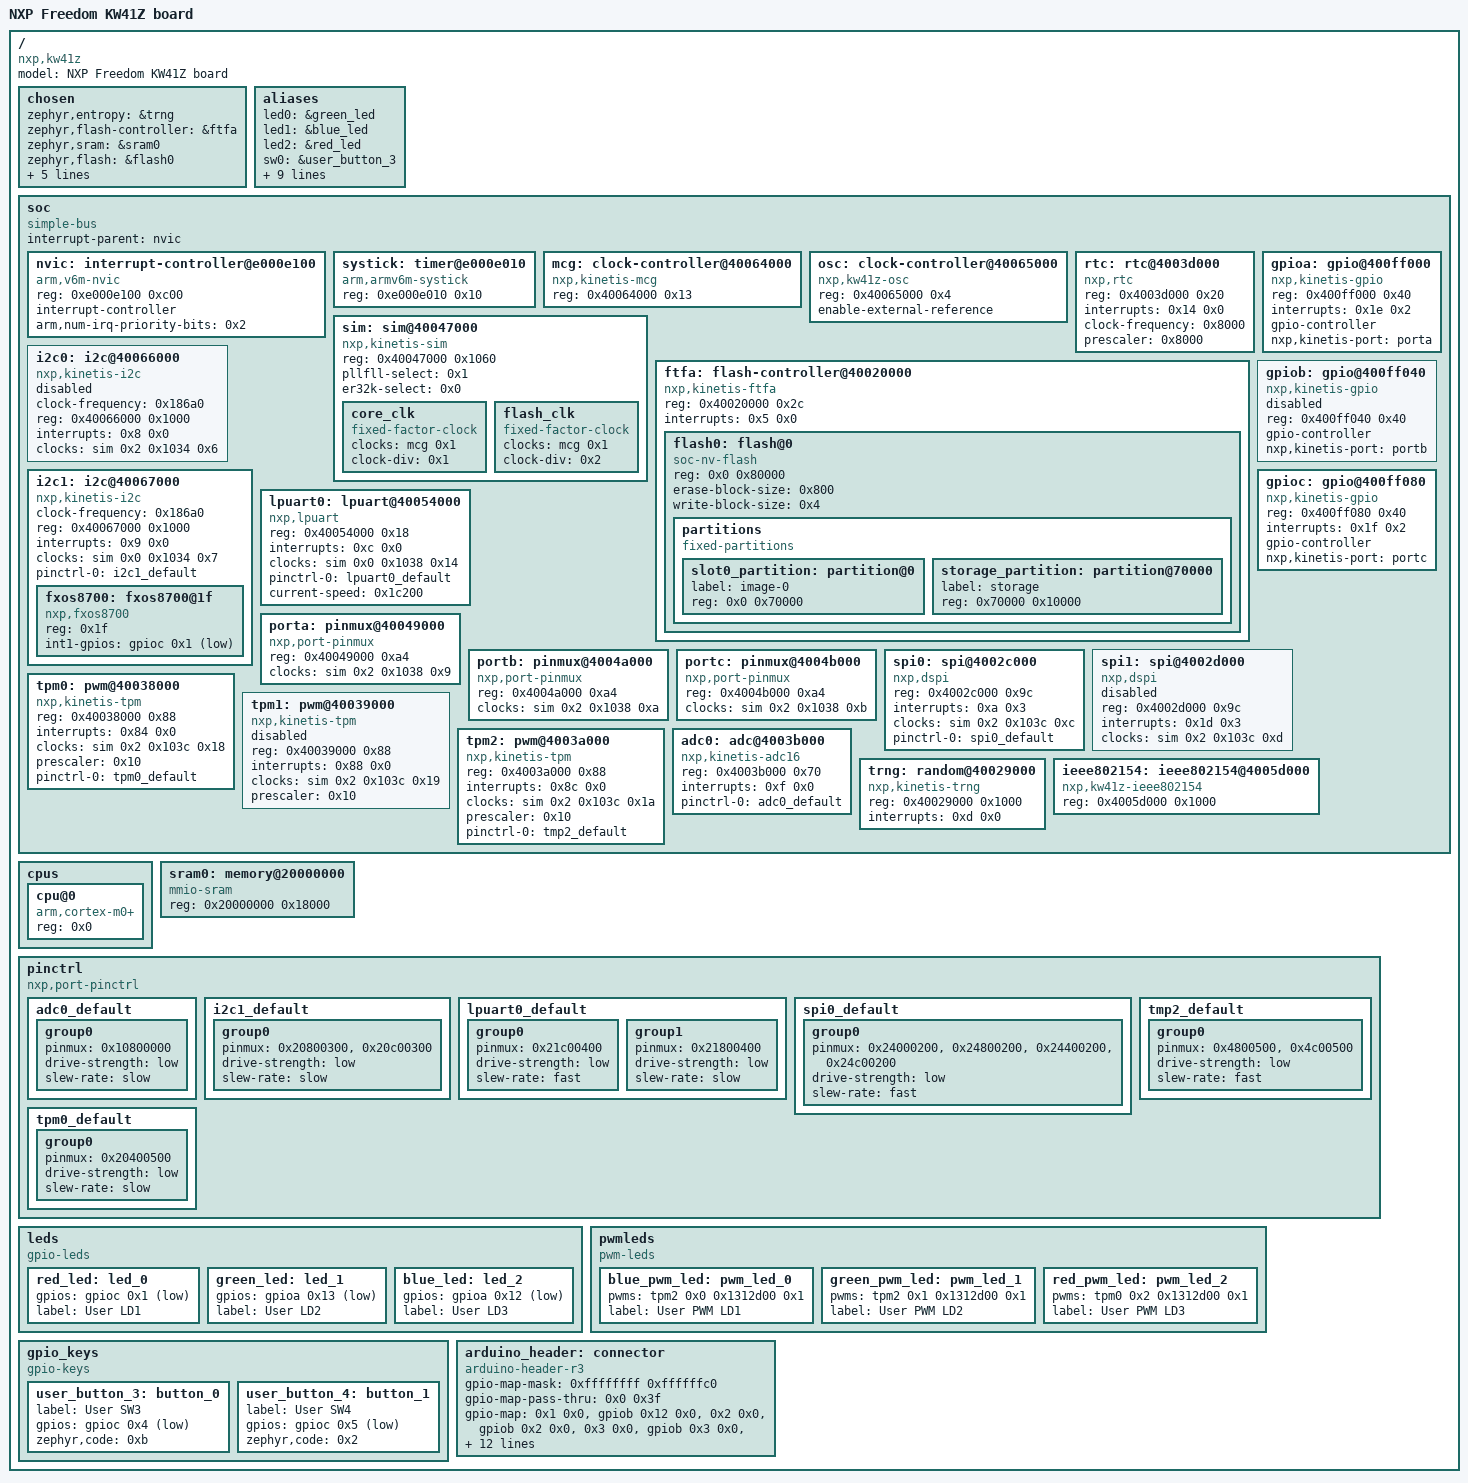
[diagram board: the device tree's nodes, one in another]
/dts-v1/;

/* node '/' defined in zephyr/dts/common/skeleton.dtsi:9 */
/ {
	#address-cells = < 0x1 >;          /* in zephyr/dts/common/skeleton.dtsi:10 */
	#size-cells = < 0x1 >;             /* in zephyr/dts/common/skeleton.dtsi:11 */
	model = "NXP Freedom KW41Z board"; /* in zephyr/boards/nxp/frdm_kw41z/frdm_kw41z.dts:11 */
	compatible = "nxp,kw41z",
	             "nxp,mkw41z4";        /* in zephyr/boards/nxp/frdm_kw41z/frdm_kw41z.dts:12 */

	/* node '/chosen' defined in zephyr/dts/common/skeleton.dtsi:13 */
	chosen {
		zephyr,entropy = &trng;                   /* in zephyr/dts/arm/nxp/nxp_kw41z.dtsi:19 */
		zephyr,flash-controller = &ftfa;          /* in zephyr/dts/arm/nxp/nxp_kw41z.dtsi:20 */
		zephyr,sram = &sram0;                     /* in zephyr/boards/nxp/frdm_kw41z/frdm_kw41z.dts:31 */
		zephyr,flash = &flash0;                   /* in zephyr/boards/nxp/frdm_kw41z/frdm_kw41z.dts:32 */
		zephyr,console = &lpuart0;                /* in zephyr/boards/nxp/frdm_kw41z/frdm_kw41z.dts:33 */
		zephyr,shell-uart = &lpuart0;             /* in zephyr/boards/nxp/frdm_kw41z/frdm_kw41z.dts:34 */
		zephyr,ieee802154 = &ieee802154;          /* in zephyr/boards/nxp/frdm_kw41z/frdm_kw41z.dts:35 */
		zephyr,code-partition = &slot0_partition; /* in zephyr/boards/nxp/frdm_kw41z/frdm_kw41z.dts:36 */
		zephyr,uart-mcumgr = &lpuart0;            /* in zephyr/boards/nxp/frdm_kw41z/frdm_kw41z.dts:37 */
	};

	/* node '/aliases' defined in zephyr/dts/common/skeleton.dtsi:15 */
	aliases {
		led0 = &green_led;              /* in zephyr/boards/nxp/frdm_kw41z/frdm_kw41z.dts:15 */
		led1 = &blue_led;               /* in zephyr/boards/nxp/frdm_kw41z/frdm_kw41z.dts:16 */
		led2 = &red_led;                /* in zephyr/boards/nxp/frdm_kw41z/frdm_kw41z.dts:17 */
		sw0 = &user_button_3;           /* in zephyr/boards/nxp/frdm_kw41z/frdm_kw41z.dts:18 */
		sw1 = &user_button_4;           /* in zephyr/boards/nxp/frdm_kw41z/frdm_kw41z.dts:19 */
		pwm-led0 = &blue_pwm_led;       /* in zephyr/boards/nxp/frdm_kw41z/frdm_kw41z.dts:20 */
		pwm-led1 = &green_pwm_led;      /* in zephyr/boards/nxp/frdm_kw41z/frdm_kw41z.dts:21 */
		pwm-led2 = &red_pwm_led;        /* in zephyr/boards/nxp/frdm_kw41z/frdm_kw41z.dts:22 */
		blue-pwm-led = &blue_pwm_led;   /* in zephyr/boards/nxp/frdm_kw41z/frdm_kw41z.dts:23 */
		green-pwm-led = &green_pwm_led; /* in zephyr/boards/nxp/frdm_kw41z/frdm_kw41z.dts:24 */
		red-pwm-led = &red_pwm_led;     /* in zephyr/boards/nxp/frdm_kw41z/frdm_kw41z.dts:25 */
		magn0 = &fxos8700;              /* in zephyr/boards/nxp/frdm_kw41z/frdm_kw41z.dts:26 */
		accel0 = &fxos8700;             /* in zephyr/boards/nxp/frdm_kw41z/frdm_kw41z.dts:27 */
	};

	/* node '/soc' defined in zephyr/dts/arm/armv6-m.dtsi:6 */
	soc {
		#address-cells = < 0x1 >;     /* in zephyr/dts/arm/armv6-m.dtsi:7 */
		#size-cells = < 0x1 >;        /* in zephyr/dts/arm/armv6-m.dtsi:8 */
		compatible = "simple-bus";    /* in zephyr/dts/arm/armv6-m.dtsi:9 */
		interrupt-parent = < &nvic >; /* in zephyr/dts/arm/armv6-m.dtsi:10 */
		ranges;                       /* in zephyr/dts/arm/armv6-m.dtsi:11 */

		/* node '/soc/interrupt-controller@e000e100' defined in zephyr/dts/arm/armv6-m.dtsi:13 */
		nvic: interrupt-controller@e000e100 {
			#address-cells = < 0x1 >;            /* in zephyr/dts/arm/armv6-m.dtsi:14 */
			compatible = "arm,v6m-nvic";         /* in zephyr/dts/arm/armv6-m.dtsi:15 */
			reg = < 0xe000e100 0xc00 >;          /* in zephyr/dts/arm/armv6-m.dtsi:16 */
			interrupt-controller;                /* in zephyr/dts/arm/armv6-m.dtsi:17 */
			#interrupt-cells = < 0x2 >;          /* in zephyr/dts/arm/armv6-m.dtsi:18 */
			arm,num-irq-priority-bits = < 0x2 >; /* in zephyr/dts/arm/nxp/nxp_kw41z.dtsi:259 */
			phandle = < 0x1 >;                   /* in zephyr/dts/arm/armv6-m.dtsi:10 */
		};

		/* node '/soc/timer@e000e010' defined in zephyr/dts/arm/armv6-m.dtsi:21 */
		systick: timer@e000e010 {
			compatible = "arm,armv6m-systick"; /* in zephyr/dts/arm/armv6-m.dtsi:22 */
			reg = < 0xe000e010 0x10 >;         /* in zephyr/dts/arm/armv6-m.dtsi:23 */
		};

		/* node '/soc/clock-controller@40064000' defined in zephyr/dts/arm/nxp/nxp_kw41z.dtsi:46 */
		mcg: clock-controller@40064000 {
			compatible = "nxp,kinetis-mcg"; /* in zephyr/dts/arm/nxp/nxp_kw41z.dtsi:47 */
			reg = < 0x40064000 0x13 >;      /* in zephyr/dts/arm/nxp/nxp_kw41z.dtsi:48 */
			#clock-cells = < 0x1 >;         /* in zephyr/dts/arm/nxp/nxp_kw41z.dtsi:49 */
			phandle = < 0x2 >;              /* in zephyr/dts/arm/nxp/nxp_kw41z.dtsi:73 */
		};

		/* node '/soc/clock-controller@40065000' defined in zephyr/dts/arm/nxp/nxp_kw41z.dtsi:52 */
		osc: clock-controller@40065000 {
			compatible = "nxp,kw41z-osc"; /* in zephyr/dts/arm/nxp/nxp_kw41z.dtsi:53 */
			reg = < 0x40065000 0x4 >;     /* in zephyr/dts/arm/nxp/nxp_kw41z.dtsi:54 */
			enable-external-reference;    /* in zephyr/dts/arm/nxp/nxp_kw41z.dtsi:55 */
		};

		/* node '/soc/rtc@4003d000' defined in zephyr/dts/arm/nxp/nxp_kw41z.dtsi:58 */
		rtc: rtc@4003d000 {
			compatible = "nxp,rtc";       /* in zephyr/dts/arm/nxp/nxp_kw41z.dtsi:59 */
			reg = < 0x4003d000 0x20 >;    /* in zephyr/dts/arm/nxp/nxp_kw41z.dtsi:60 */
			interrupts = < 0x14 0x0 >;    /* in zephyr/dts/arm/nxp/nxp_kw41z.dtsi:61 */
			clock-frequency = < 0x8000 >; /* in zephyr/dts/arm/nxp/nxp_kw41z.dtsi:62 */
			prescaler = < 0x8000 >;       /* in zephyr/dts/arm/nxp/nxp_kw41z.dtsi:63 */
		};

		/* node '/soc/sim@40047000' defined in zephyr/dts/arm/nxp/nxp_kw41z.dtsi:66 */
		sim: sim@40047000 {
			compatible = "nxp,kinetis-sim"; /* in zephyr/dts/arm/nxp/nxp_kw41z.dtsi:67 */
			reg = < 0x40047000 0x1060 >;    /* in zephyr/dts/arm/nxp/nxp_kw41z.dtsi:68 */
			#clock-cells = < 0x3 >;         /* in zephyr/dts/arm/nxp/nxp_kw41z.dtsi:69 */
			pllfll-select = < 0x1 >;        /* in zephyr/boards/nxp/frdm_kw41z/frdm_kw41z.dts:124 */
			er32k-select = < 0x0 >;         /* in zephyr/boards/nxp/frdm_kw41z/frdm_kw41z.dts:125 */
			phandle = < 0x3 >;              /* in zephyr/dts/arm/nxp/nxp_kw41z.dtsi:110 */

			/* node '/soc/sim@40047000/core_clk' defined in zephyr/dts/arm/nxp/nxp_kw41z.dtsi:71 */
			core_clk {
				compatible = "fixed-factor-clock"; /* in zephyr/dts/arm/nxp/nxp_kw41z.dtsi:72 */
				clocks = < &mcg 0x1 >;             /* in zephyr/dts/arm/nxp/nxp_kw41z.dtsi:73 */
				clock-div = < 0x1 >;               /* in zephyr/dts/arm/nxp/nxp_kw41z.dtsi:74 */
				#clock-cells = < 0x0 >;            /* in zephyr/dts/arm/nxp/nxp_kw41z.dtsi:75 */
			};

			/* node '/soc/sim@40047000/flash_clk' defined in zephyr/dts/arm/nxp/nxp_kw41z.dtsi:78 */
			flash_clk {
				compatible = "fixed-factor-clock"; /* in zephyr/dts/arm/nxp/nxp_kw41z.dtsi:79 */
				clocks = < &mcg 0x1 >;             /* in zephyr/dts/arm/nxp/nxp_kw41z.dtsi:80 */
				clock-div = < 0x2 >;               /* in zephyr/dts/arm/nxp/nxp_kw41z.dtsi:81 */
				#clock-cells = < 0x0 >;            /* in zephyr/dts/arm/nxp/nxp_kw41z.dtsi:82 */
			};
		};

		/* node '/soc/flash-controller@40020000' defined in zephyr/dts/arm/nxp/nxp_kw41z.dtsi:86 */
		ftfa: flash-controller@40020000 {
			compatible = "nxp,kinetis-ftfa"; /* in zephyr/dts/arm/nxp/nxp_kw41z.dtsi:87 */
			reg = < 0x40020000 0x2c >;       /* in zephyr/dts/arm/nxp/nxp_kw41z.dtsi:88 */
			interrupts = < 0x5 0x0 >;        /* in zephyr/dts/arm/nxp/nxp_kw41z.dtsi:89 */
			status = "okay";                 /* in zephyr/dts/arm/nxp/nxp_kw41z.dtsi:90 */
			#address-cells = < 0x1 >;        /* in zephyr/dts/arm/nxp/nxp_kw41z.dtsi:92 */
			#size-cells = < 0x1 >;           /* in zephyr/dts/arm/nxp/nxp_kw41z.dtsi:93 */

			/* node '/soc/flash-controller@40020000/flash@0' defined in zephyr/dts/arm/nxp/nxp_kw41z.dtsi:95 */
			flash0: flash@0 {
				compatible = "soc-nv-flash";  /* in zephyr/dts/arm/nxp/nxp_kw41z.dtsi:96 */
				reg = < 0x0 0x80000 >;        /* in zephyr/dts/arm/nxp/nxp_kw41z.dtsi:97 */
				erase-block-size = < 0x800 >; /* in zephyr/dts/arm/nxp/nxp_kw41z.dtsi:98 */
				write-block-size = < 0x4 >;   /* in zephyr/dts/arm/nxp/nxp_kw41z.dtsi:99 */

				/* node '/soc/flash-controller@40020000/flash@0/partitions' defined in zephyr/boards/nxp/frdm_kw41z/frdm_kw41z.dts:188 */
				partitions {
					compatible = "fixed-partitions"; /* in zephyr/boards/nxp/frdm_kw41z/frdm_kw41z.dts:189 */
					#address-cells = < 0x1 >;        /* in zephyr/boards/nxp/frdm_kw41z/frdm_kw41z.dts:190 */
					#size-cells = < 0x1 >;           /* in zephyr/boards/nxp/frdm_kw41z/frdm_kw41z.dts:191 */

					/* node '/soc/flash-controller@40020000/flash@0/partitions/partition@0' defined in zephyr/boards/nxp/frdm_kw41z/frdm_kw41z.dts:193 */
					slot0_partition: partition@0 {
						label = "image-0";     /* in zephyr/boards/nxp/frdm_kw41z/frdm_kw41z.dts:194 */
						reg = < 0x0 0x70000 >; /* in zephyr/boards/nxp/frdm_kw41z/frdm_kw41z.dts:195 */
					};

					/* node '/soc/flash-controller@40020000/flash@0/partitions/partition@70000' defined in zephyr/boards/nxp/frdm_kw41z/frdm_kw41z.dts:198 */
					storage_partition: partition@70000 {
						label = "storage";         /* in zephyr/boards/nxp/frdm_kw41z/frdm_kw41z.dts:199 */
						reg = < 0x70000 0x10000 >; /* in zephyr/boards/nxp/frdm_kw41z/frdm_kw41z.dts:200 */
					};
				};
			};
		};

		/* node '/soc/i2c@40066000' defined in zephyr/dts/arm/nxp/nxp_kw41z.dtsi:103 */
		i2c0: i2c@40066000 {
			compatible = "nxp,kinetis-i2c";   /* in zephyr/dts/arm/nxp/nxp_kw41z.dtsi:104 */
			clock-frequency = < 0x186a0 >;    /* in zephyr/dts/arm/nxp/nxp_kw41z.dtsi:105 */
			#address-cells = < 0x1 >;         /* in zephyr/dts/arm/nxp/nxp_kw41z.dtsi:106 */
			#size-cells = < 0x0 >;            /* in zephyr/dts/arm/nxp/nxp_kw41z.dtsi:107 */
			reg = < 0x40066000 0x1000 >;      /* in zephyr/dts/arm/nxp/nxp_kw41z.dtsi:108 */
			interrupts = < 0x8 0x0 >;         /* in zephyr/dts/arm/nxp/nxp_kw41z.dtsi:109 */
			clocks = < &sim 0x2 0x1034 0x6 >; /* in zephyr/dts/arm/nxp/nxp_kw41z.dtsi:110 */
			status = "disabled";              /* in zephyr/dts/arm/nxp/nxp_kw41z.dtsi:111 */
		};

		/* node '/soc/i2c@40067000' defined in zephyr/dts/arm/nxp/nxp_kw41z.dtsi:114 */
		i2c1: i2c@40067000 {
			compatible = "nxp,kinetis-i2c";   /* in zephyr/dts/arm/nxp/nxp_kw41z.dtsi:115 */
			clock-frequency = < 0x186a0 >;    /* in zephyr/dts/arm/nxp/nxp_kw41z.dtsi:116 */
			#address-cells = < 0x1 >;         /* in zephyr/dts/arm/nxp/nxp_kw41z.dtsi:117 */
			#size-cells = < 0x0 >;            /* in zephyr/dts/arm/nxp/nxp_kw41z.dtsi:118 */
			reg = < 0x40067000 0x1000 >;      /* in zephyr/dts/arm/nxp/nxp_kw41z.dtsi:119 */
			interrupts = < 0x9 0x0 >;         /* in zephyr/dts/arm/nxp/nxp_kw41z.dtsi:120 */
			clocks = < &sim 0x0 0x1034 0x7 >; /* in zephyr/dts/arm/nxp/nxp_kw41z.dtsi:121 */
			status = "okay";                  /* in zephyr/boards/nxp/frdm_kw41z/frdm_kw41z.dts:135 */
			pinctrl-0 = < &i2c1_default >;    /* in zephyr/boards/nxp/frdm_kw41z/frdm_kw41z.dts:136 */
			pinctrl-names = "default";        /* in zephyr/boards/nxp/frdm_kw41z/frdm_kw41z.dts:137 */

			/* node '/soc/i2c@40067000/fxos8700@1f' defined in zephyr/boards/nxp/frdm_kw41z/frdm_kw41z.dts:139 */
			fxos8700: fxos8700@1f {
				compatible = "nxp,fxos8700";     /* in zephyr/boards/nxp/frdm_kw41z/frdm_kw41z.dts:140 */
				reg = < 0x1f >;                  /* in zephyr/boards/nxp/frdm_kw41z/frdm_kw41z.dts:141 */
				int1-gpios = < &gpioc 0x1 0x1 >; /* in zephyr/boards/nxp/frdm_kw41z/frdm_kw41z.dts:142 */
			};
		};

		/* node '/soc/lpuart@40054000' defined in zephyr/dts/arm/nxp/nxp_kw41z.dtsi:125 */
		lpuart0: lpuart@40054000 {
			compatible = "nxp,lpuart";         /* in zephyr/dts/arm/nxp/nxp_kw41z.dtsi:126 */
			reg = < 0x40054000 0x18 >;         /* in zephyr/dts/arm/nxp/nxp_kw41z.dtsi:127 */
			interrupts = < 0xc 0x0 >;          /* in zephyr/dts/arm/nxp/nxp_kw41z.dtsi:128 */
			clocks = < &sim 0x0 0x1038 0x14 >; /* in zephyr/dts/arm/nxp/nxp_kw41z.dtsi:129 */
			status = "okay";                   /* in zephyr/boards/nxp/frdm_kw41z/frdm_kw41z.dts:147 */
			pinctrl-0 = < &lpuart0_default >;  /* in zephyr/boards/nxp/frdm_kw41z/frdm_kw41z.dts:148 */
			pinctrl-names = "default";         /* in zephyr/boards/nxp/frdm_kw41z/frdm_kw41z.dts:149 */
			current-speed = < 0x1c200 >;       /* in zephyr/boards/nxp/frdm_kw41z/frdm_kw41z.dts:150 */
		};

		/* node '/soc/pinmux@40049000' defined in zephyr/dts/arm/nxp/nxp_kw41z.dtsi:134 */
		porta: pinmux@40049000 {
			compatible = "nxp,port-pinmux";   /* in zephyr/dts/arm/nxp/nxp_kw41z.dtsi:135 */
			reg = < 0x40049000 0xa4 >;        /* in zephyr/dts/arm/nxp/nxp_kw41z.dtsi:136 */
			clocks = < &sim 0x2 0x1038 0x9 >; /* in zephyr/dts/arm/nxp/nxp_kw41z.dtsi:137 */
			phandle = < 0x7 >;                /* in zephyr/dts/arm/nxp/nxp_kw41z.dtsi:159 */
		};

		/* node '/soc/pinmux@4004a000' defined in zephyr/dts/arm/nxp/nxp_kw41z.dtsi:140 */
		portb: pinmux@4004a000 {
			compatible = "nxp,port-pinmux";   /* in zephyr/dts/arm/nxp/nxp_kw41z.dtsi:141 */
			reg = < 0x4004a000 0xa4 >;        /* in zephyr/dts/arm/nxp/nxp_kw41z.dtsi:142 */
			clocks = < &sim 0x2 0x1038 0xa >; /* in zephyr/dts/arm/nxp/nxp_kw41z.dtsi:143 */
			phandle = < 0x8 >;                /* in zephyr/dts/arm/nxp/nxp_kw41z.dtsi:168 */
		};

		/* node '/soc/pinmux@4004b000' defined in zephyr/dts/arm/nxp/nxp_kw41z.dtsi:146 */
		portc: pinmux@4004b000 {
			compatible = "nxp,port-pinmux";   /* in zephyr/dts/arm/nxp/nxp_kw41z.dtsi:147 */
			reg = < 0x4004b000 0xa4 >;        /* in zephyr/dts/arm/nxp/nxp_kw41z.dtsi:148 */
			clocks = < &sim 0x2 0x1038 0xb >; /* in zephyr/dts/arm/nxp/nxp_kw41z.dtsi:149 */
			phandle = < 0x9 >;                /* in zephyr/dts/arm/nxp/nxp_kw41z.dtsi:178 */
		};

		/* node '/soc/gpio@400ff000' defined in zephyr/dts/arm/nxp/nxp_kw41z.dtsi:152 */
		gpioa: gpio@400ff000 {
			compatible = "nxp,kinetis-gpio"; /* in zephyr/dts/arm/nxp/nxp_kw41z.dtsi:153 */
			reg = < 0x400ff000 0x40 >;       /* in zephyr/dts/arm/nxp/nxp_kw41z.dtsi:155 */
			interrupts = < 0x1e 0x2 >;       /* in zephyr/dts/arm/nxp/nxp_kw41z.dtsi:156 */
			gpio-controller;                 /* in zephyr/dts/arm/nxp/nxp_kw41z.dtsi:157 */
			#gpio-cells = < 0x2 >;           /* in zephyr/dts/arm/nxp/nxp_kw41z.dtsi:158 */
			nxp,kinetis-port = < &porta >;   /* in zephyr/dts/arm/nxp/nxp_kw41z.dtsi:159 */
			status = "okay";                 /* in zephyr/boards/nxp/frdm_kw41z/frdm_kw41z.dts:154 */
			phandle = < 0xe >;               /* in zephyr/boards/nxp/frdm_kw41z/frdm_kw41z.dts:49 */
		};

		/* node '/soc/gpio@400ff040' defined in zephyr/dts/arm/nxp/nxp_kw41z.dtsi:162 */
		gpiob: gpio@400ff040 {
			compatible = "nxp,kinetis-gpio"; /* in zephyr/dts/arm/nxp/nxp_kw41z.dtsi:163 */
			status = "disabled";             /* in zephyr/dts/arm/nxp/nxp_kw41z.dtsi:164 */
			reg = < 0x400ff040 0x40 >;       /* in zephyr/dts/arm/nxp/nxp_kw41z.dtsi:165 */
			gpio-controller;                 /* in zephyr/dts/arm/nxp/nxp_kw41z.dtsi:166 */
			#gpio-cells = < 0x2 >;           /* in zephyr/dts/arm/nxp/nxp_kw41z.dtsi:167 */
			nxp,kinetis-port = < &portb >;   /* in zephyr/dts/arm/nxp/nxp_kw41z.dtsi:168 */
			phandle = < 0x11 >;              /* in zephyr/boards/nxp/frdm_kw41z/frdm_kw41z.dts:99 */
		};

		/* node '/soc/gpio@400ff080' defined in zephyr/dts/arm/nxp/nxp_kw41z.dtsi:171 */
		gpioc: gpio@400ff080 {
			compatible = "nxp,kinetis-gpio"; /* in zephyr/dts/arm/nxp/nxp_kw41z.dtsi:172 */
			reg = < 0x400ff080 0x40 >;       /* in zephyr/dts/arm/nxp/nxp_kw41z.dtsi:174 */
			interrupts = < 0x1f 0x2 >;       /* in zephyr/dts/arm/nxp/nxp_kw41z.dtsi:175 */
			gpio-controller;                 /* in zephyr/dts/arm/nxp/nxp_kw41z.dtsi:176 */
			#gpio-cells = < 0x2 >;           /* in zephyr/dts/arm/nxp/nxp_kw41z.dtsi:177 */
			nxp,kinetis-port = < &portc >;   /* in zephyr/dts/arm/nxp/nxp_kw41z.dtsi:178 */
			status = "okay";                 /* in zephyr/boards/nxp/frdm_kw41z/frdm_kw41z.dts:158 */
			phandle = < 0x5 >;               /* in zephyr/boards/nxp/frdm_kw41z/frdm_kw41z.dts:142 */
		};

		/* node '/soc/spi@4002c000' defined in zephyr/dts/arm/nxp/nxp_kw41z.dtsi:181 */
		spi0: spi@4002c000 {
			compatible = "nxp,dspi";          /* in zephyr/dts/arm/nxp/nxp_kw41z.dtsi:182 */
			reg = < 0x4002c000 0x9c >;        /* in zephyr/dts/arm/nxp/nxp_kw41z.dtsi:183 */
			interrupts = < 0xa 0x3 >;         /* in zephyr/dts/arm/nxp/nxp_kw41z.dtsi:184 */
			clocks = < &sim 0x2 0x103c 0xc >; /* in zephyr/dts/arm/nxp/nxp_kw41z.dtsi:185 */
			#address-cells = < 0x1 >;         /* in zephyr/dts/arm/nxp/nxp_kw41z.dtsi:188 */
			#size-cells = < 0x0 >;            /* in zephyr/dts/arm/nxp/nxp_kw41z.dtsi:189 */
			status = "okay";                  /* in zephyr/boards/nxp/frdm_kw41z/frdm_kw41z.dts:162 */
			pinctrl-0 = < &spi0_default >;    /* in zephyr/boards/nxp/frdm_kw41z/frdm_kw41z.dts:163 */
			pinctrl-names = "default";        /* in zephyr/boards/nxp/frdm_kw41z/frdm_kw41z.dts:164 */
		};

		/* node '/soc/spi@4002d000' defined in zephyr/dts/arm/nxp/nxp_kw41z.dtsi:192 */
		spi1: spi@4002d000 {
			compatible = "nxp,dspi";          /* in zephyr/dts/arm/nxp/nxp_kw41z.dtsi:193 */
			reg = < 0x4002d000 0x9c >;        /* in zephyr/dts/arm/nxp/nxp_kw41z.dtsi:194 */
			interrupts = < 0x1d 0x3 >;        /* in zephyr/dts/arm/nxp/nxp_kw41z.dtsi:195 */
			clocks = < &sim 0x2 0x103c 0xd >; /* in zephyr/dts/arm/nxp/nxp_kw41z.dtsi:196 */
			status = "disabled";              /* in zephyr/dts/arm/nxp/nxp_kw41z.dtsi:197 */
			#address-cells = < 0x1 >;         /* in zephyr/dts/arm/nxp/nxp_kw41z.dtsi:198 */
			#size-cells = < 0x0 >;            /* in zephyr/dts/arm/nxp/nxp_kw41z.dtsi:199 */
		};

		/* node '/soc/pwm@40038000' defined in zephyr/dts/arm/nxp/nxp_kw41z.dtsi:202 */
		tpm0: pwm@40038000 {
			compatible = "nxp,kinetis-tpm";    /* in zephyr/dts/arm/nxp/nxp_kw41z.dtsi:203 */
			reg = < 0x40038000 0x88 >;         /* in zephyr/dts/arm/nxp/nxp_kw41z.dtsi:204 */
			interrupts = < 0x84 0x0 >;         /* in zephyr/dts/arm/nxp/nxp_kw41z.dtsi:205 */
			clocks = < &sim 0x2 0x103c 0x18 >; /* in zephyr/dts/arm/nxp/nxp_kw41z.dtsi:207 */
			prescaler = < 0x10 >;              /* in zephyr/dts/arm/nxp/nxp_kw41z.dtsi:208 */
			#pwm-cells = < 0x3 >;              /* in zephyr/dts/arm/nxp/nxp_kw41z.dtsi:210 */
			status = "okay";                   /* in zephyr/boards/nxp/frdm_kw41z/frdm_kw41z.dts:168 */
			pinctrl-0 = < &tpm0_default >;     /* in zephyr/boards/nxp/frdm_kw41z/frdm_kw41z.dts:169 */
			pinctrl-names = "default";         /* in zephyr/boards/nxp/frdm_kw41z/frdm_kw41z.dts:170 */
			phandle = < 0x10 >;                /* in zephyr/boards/nxp/frdm_kw41z/frdm_kw41z.dts:73 */
		};

		/* node '/soc/pwm@40039000' defined in zephyr/dts/arm/nxp/nxp_kw41z.dtsi:213 */
		tpm1: pwm@40039000 {
			compatible = "nxp,kinetis-tpm";    /* in zephyr/dts/arm/nxp/nxp_kw41z.dtsi:214 */
			reg = < 0x40039000 0x88 >;         /* in zephyr/dts/arm/nxp/nxp_kw41z.dtsi:215 */
			interrupts = < 0x88 0x0 >;         /* in zephyr/dts/arm/nxp/nxp_kw41z.dtsi:216 */
			clocks = < &sim 0x2 0x103c 0x19 >; /* in zephyr/dts/arm/nxp/nxp_kw41z.dtsi:218 */
			prescaler = < 0x10 >;              /* in zephyr/dts/arm/nxp/nxp_kw41z.dtsi:219 */
			#pwm-cells = < 0x3 >;              /* in zephyr/dts/arm/nxp/nxp_kw41z.dtsi:221 */
			status = "disabled";               /* in zephyr/boards/nxp/frdm_kw41z/frdm_kw41z.dts:174 */
		};

		/* node '/soc/pwm@4003a000' defined in zephyr/dts/arm/nxp/nxp_kw41z.dtsi:224 */
		tpm2: pwm@4003a000 {
			compatible = "nxp,kinetis-tpm";    /* in zephyr/dts/arm/nxp/nxp_kw41z.dtsi:225 */
			reg = < 0x4003a000 0x88 >;         /* in zephyr/dts/arm/nxp/nxp_kw41z.dtsi:226 */
			interrupts = < 0x8c 0x0 >;         /* in zephyr/dts/arm/nxp/nxp_kw41z.dtsi:227 */
			clocks = < &sim 0x2 0x103c 0x1a >; /* in zephyr/dts/arm/nxp/nxp_kw41z.dtsi:229 */
			prescaler = < 0x10 >;              /* in zephyr/dts/arm/nxp/nxp_kw41z.dtsi:230 */
			#pwm-cells = < 0x3 >;              /* in zephyr/dts/arm/nxp/nxp_kw41z.dtsi:232 */
			status = "okay";                   /* in zephyr/boards/nxp/frdm_kw41z/frdm_kw41z.dts:178 */
			pinctrl-0 = < &tmp2_default >;     /* in zephyr/boards/nxp/frdm_kw41z/frdm_kw41z.dts:179 */
			pinctrl-names = "default";         /* in zephyr/boards/nxp/frdm_kw41z/frdm_kw41z.dts:180 */
			phandle = < 0xf >;                 /* in zephyr/boards/nxp/frdm_kw41z/frdm_kw41z.dts:63 */
		};

		/* node '/soc/adc@4003b000' defined in zephyr/dts/arm/nxp/nxp_kw41z.dtsi:235 */
		adc0: adc@4003b000 {
			compatible = "nxp,kinetis-adc16"; /* in zephyr/dts/arm/nxp/nxp_kw41z.dtsi:236 */
			reg = < 0x4003b000 0x70 >;        /* in zephyr/dts/arm/nxp/nxp_kw41z.dtsi:237 */
			interrupts = < 0xf 0x0 >;         /* in zephyr/dts/arm/nxp/nxp_kw41z.dtsi:238 */
			#io-channel-cells = < 0x1 >;      /* in zephyr/dts/arm/nxp/nxp_kw41z.dtsi:240 */
			status = "okay";                  /* in zephyr/boards/nxp/frdm_kw41z/frdm_kw41z.dts:129 */
			pinctrl-0 = < &adc0_default >;    /* in zephyr/boards/nxp/frdm_kw41z/frdm_kw41z.dts:130 */
			pinctrl-names = "default";        /* in zephyr/boards/nxp/frdm_kw41z/frdm_kw41z.dts:131 */
		};

		/* node '/soc/random@40029000' defined in zephyr/dts/arm/nxp/nxp_kw41z.dtsi:243 */
		trng: random@40029000 {
			compatible = "nxp,kinetis-trng"; /* in zephyr/dts/arm/nxp/nxp_kw41z.dtsi:244 */
			reg = < 0x40029000 0x1000 >;     /* in zephyr/dts/arm/nxp/nxp_kw41z.dtsi:245 */
			status = "okay";                 /* in zephyr/dts/arm/nxp/nxp_kw41z.dtsi:246 */
			interrupts = < 0xd 0x0 >;        /* in zephyr/dts/arm/nxp/nxp_kw41z.dtsi:247 */
		};

		/* node '/soc/ieee802154@4005d000' defined in zephyr/dts/arm/nxp/nxp_kw41z.dtsi:250 */
		ieee802154: ieee802154@4005d000 {
			compatible = "nxp,kw41z-ieee802154"; /* in zephyr/dts/arm/nxp/nxp_kw41z.dtsi:251 */
			reg = < 0x4005d000 0x1000 >;         /* in zephyr/dts/arm/nxp/nxp_kw41z.dtsi:252 */
			status = "okay";                     /* in zephyr/boards/nxp/frdm_kw41z/frdm_kw41z.dts:184 */
		};
	};

	/* node '/cpus' defined in zephyr/dts/arm/nxp/nxp_kw41z.dtsi:23 */
	cpus {
		#address-cells = < 0x1 >; /* in zephyr/dts/arm/nxp/nxp_kw41z.dtsi:24 */
		#size-cells = < 0x0 >;    /* in zephyr/dts/arm/nxp/nxp_kw41z.dtsi:25 */

		/* node '/cpus/cpu@0' defined in zephyr/dts/arm/nxp/nxp_kw41z.dtsi:27 */
		cpu@0 {
			device_type = "cpu";           /* in zephyr/dts/arm/nxp/nxp_kw41z.dtsi:28 */
			compatible = "arm,cortex-m0+"; /* in zephyr/dts/arm/nxp/nxp_kw41z.dtsi:29 */
			reg = < 0x0 >;                 /* in zephyr/dts/arm/nxp/nxp_kw41z.dtsi:30 */
		};
	};

	/* node '/memory@20000000' defined in zephyr/dts/arm/nxp/nxp_kw41z.dtsi:34 */
	sram0: memory@20000000 {
		compatible = "mmio-sram";     /* in zephyr/dts/arm/nxp/nxp_kw41z.dtsi:35 */
		reg = < 0x20000000 0x18000 >; /* in zephyr/dts/arm/nxp/nxp_kw41z.dtsi:36 */
	};

	/* node '/pinctrl' defined in zephyr/dts/arm/nxp/nxp_kw41z.dtsi:40 */
	pinctrl: pinctrl {
		compatible = "nxp,port-pinctrl"; /* in zephyr/dts/arm/nxp/nxp_kw41z.dtsi:41 */
		status = "okay";                 /* in zephyr/dts/arm/nxp/nxp_kw41z.dtsi:42 */

		/* node '/pinctrl/adc0_default' defined in zephyr/boards/nxp/frdm_kw41z/frdm_kw41z-pinctrl.dtsi:12 */
		adc0_default: adc0_default {
			phandle = < 0xd >; /* in zephyr/boards/nxp/frdm_kw41z/frdm_kw41z.dts:130 */

			/* node '/pinctrl/adc0_default/group0' defined in zephyr/boards/nxp/frdm_kw41z/frdm_kw41z-pinctrl.dtsi:13 */
			group0 {
				pinmux = < 0x10800000 >; /* in zephyr/boards/nxp/frdm_kw41z/frdm_kw41z-pinctrl.dtsi:14 */
				drive-strength = "low";  /* in zephyr/boards/nxp/frdm_kw41z/frdm_kw41z-pinctrl.dtsi:15 */
				slew-rate = "slow";      /* in zephyr/boards/nxp/frdm_kw41z/frdm_kw41z-pinctrl.dtsi:16 */
			};
		};

		/* node '/pinctrl/i2c1_default' defined in zephyr/boards/nxp/frdm_kw41z/frdm_kw41z-pinctrl.dtsi:20 */
		i2c1_default: i2c1_default {
			phandle = < 0x4 >; /* in zephyr/boards/nxp/frdm_kw41z/frdm_kw41z.dts:136 */

			/* node '/pinctrl/i2c1_default/group0' defined in zephyr/boards/nxp/frdm_kw41z/frdm_kw41z-pinctrl.dtsi:21 */
			group0 {
				pinmux = < 0x20800300 >,
				         < 0x20c00300 >; /* in zephyr/boards/nxp/frdm_kw41z/frdm_kw41z-pinctrl.dtsi:22 */
				drive-strength = "low";  /* in zephyr/boards/nxp/frdm_kw41z/frdm_kw41z-pinctrl.dtsi:24 */
				slew-rate = "slow";      /* in zephyr/boards/nxp/frdm_kw41z/frdm_kw41z-pinctrl.dtsi:25 */
			};
		};

		/* node '/pinctrl/lpuart0_default' defined in zephyr/boards/nxp/frdm_kw41z/frdm_kw41z-pinctrl.dtsi:29 */
		lpuart0_default: lpuart0_default {
			phandle = < 0x6 >; /* in zephyr/boards/nxp/frdm_kw41z/frdm_kw41z.dts:148 */

			/* node '/pinctrl/lpuart0_default/group0' defined in zephyr/boards/nxp/frdm_kw41z/frdm_kw41z-pinctrl.dtsi:30 */
			group0 {
				pinmux = < 0x21c00400 >; /* in zephyr/boards/nxp/frdm_kw41z/frdm_kw41z-pinctrl.dtsi:31 */
				drive-strength = "low";  /* in zephyr/boards/nxp/frdm_kw41z/frdm_kw41z-pinctrl.dtsi:32 */
				slew-rate = "fast";      /* in zephyr/boards/nxp/frdm_kw41z/frdm_kw41z-pinctrl.dtsi:33 */
			};

			/* node '/pinctrl/lpuart0_default/group1' defined in zephyr/boards/nxp/frdm_kw41z/frdm_kw41z-pinctrl.dtsi:36 */
			group1 {
				pinmux = < 0x21800400 >; /* in zephyr/boards/nxp/frdm_kw41z/frdm_kw41z-pinctrl.dtsi:37 */
				drive-strength = "low";  /* in zephyr/boards/nxp/frdm_kw41z/frdm_kw41z-pinctrl.dtsi:38 */
				slew-rate = "slow";      /* in zephyr/boards/nxp/frdm_kw41z/frdm_kw41z-pinctrl.dtsi:39 */
			};
		};

		/* node '/pinctrl/spi0_default' defined in zephyr/boards/nxp/frdm_kw41z/frdm_kw41z-pinctrl.dtsi:43 */
		spi0_default: spi0_default {
			phandle = < 0xa >; /* in zephyr/boards/nxp/frdm_kw41z/frdm_kw41z.dts:163 */

			/* node '/pinctrl/spi0_default/group0' defined in zephyr/boards/nxp/frdm_kw41z/frdm_kw41z-pinctrl.dtsi:44 */
			group0 {
				pinmux = < 0x24000200 >,
				         < 0x24800200 >,
				         < 0x24400200 >,
				         < 0x24c00200 >; /* in zephyr/boards/nxp/frdm_kw41z/frdm_kw41z-pinctrl.dtsi:45 */
				drive-strength = "low";  /* in zephyr/boards/nxp/frdm_kw41z/frdm_kw41z-pinctrl.dtsi:49 */
				slew-rate = "fast";      /* in zephyr/boards/nxp/frdm_kw41z/frdm_kw41z-pinctrl.dtsi:50 */
			};
		};

		/* node '/pinctrl/tmp2_default' defined in zephyr/boards/nxp/frdm_kw41z/frdm_kw41z-pinctrl.dtsi:54 */
		tmp2_default: tmp2_default {
			phandle = < 0xc >; /* in zephyr/boards/nxp/frdm_kw41z/frdm_kw41z.dts:179 */

			/* node '/pinctrl/tmp2_default/group0' defined in zephyr/boards/nxp/frdm_kw41z/frdm_kw41z-pinctrl.dtsi:55 */
			group0 {
				pinmux = < 0x4800500 >,
				         < 0x4c00500 >; /* in zephyr/boards/nxp/frdm_kw41z/frdm_kw41z-pinctrl.dtsi:56 */
				drive-strength = "low"; /* in zephyr/boards/nxp/frdm_kw41z/frdm_kw41z-pinctrl.dtsi:58 */
				slew-rate = "fast";     /* in zephyr/boards/nxp/frdm_kw41z/frdm_kw41z-pinctrl.dtsi:59 */
			};
		};

		/* node '/pinctrl/tpm0_default' defined in zephyr/boards/nxp/frdm_kw41z/frdm_kw41z-pinctrl.dtsi:63 */
		tpm0_default: tpm0_default {
			phandle = < 0xb >; /* in zephyr/boards/nxp/frdm_kw41z/frdm_kw41z.dts:169 */

			/* node '/pinctrl/tpm0_default/group0' defined in zephyr/boards/nxp/frdm_kw41z/frdm_kw41z-pinctrl.dtsi:64 */
			group0 {
				pinmux = < 0x20400500 >; /* in zephyr/boards/nxp/frdm_kw41z/frdm_kw41z-pinctrl.dtsi:65 */
				drive-strength = "low";  /* in zephyr/boards/nxp/frdm_kw41z/frdm_kw41z-pinctrl.dtsi:66 */
				slew-rate = "slow";      /* in zephyr/boards/nxp/frdm_kw41z/frdm_kw41z-pinctrl.dtsi:67 */
			};
		};
	};

	/* node '/leds' defined in zephyr/boards/nxp/frdm_kw41z/frdm_kw41z.dts:40 */
	leds {
		compatible = "gpio-leds"; /* in zephyr/boards/nxp/frdm_kw41z/frdm_kw41z.dts:41 */

		/* node '/leds/led_0' defined in zephyr/boards/nxp/frdm_kw41z/frdm_kw41z.dts:43 */
		red_led: led_0 {
			gpios = < &gpioc 0x1 0x1 >; /* in zephyr/boards/nxp/frdm_kw41z/frdm_kw41z.dts:44 */
			label = "User LD1";         /* in zephyr/boards/nxp/frdm_kw41z/frdm_kw41z.dts:45 */
		};

		/* node '/leds/led_1' defined in zephyr/boards/nxp/frdm_kw41z/frdm_kw41z.dts:48 */
		green_led: led_1 {
			gpios = < &gpioa 0x13 0x1 >; /* in zephyr/boards/nxp/frdm_kw41z/frdm_kw41z.dts:49 */
			label = "User LD2";          /* in zephyr/boards/nxp/frdm_kw41z/frdm_kw41z.dts:50 */
		};

		/* node '/leds/led_2' defined in zephyr/boards/nxp/frdm_kw41z/frdm_kw41z.dts:53 */
		blue_led: led_2 {
			gpios = < &gpioa 0x12 0x1 >; /* in zephyr/boards/nxp/frdm_kw41z/frdm_kw41z.dts:54 */
			label = "User LD3";          /* in zephyr/boards/nxp/frdm_kw41z/frdm_kw41z.dts:55 */
		};
	};

	/* node '/pwmleds' defined in zephyr/boards/nxp/frdm_kw41z/frdm_kw41z.dts:59 */
	pwmleds {
		compatible = "pwm-leds"; /* in zephyr/boards/nxp/frdm_kw41z/frdm_kw41z.dts:60 */

		/* node '/pwmleds/pwm_led_0' defined in zephyr/boards/nxp/frdm_kw41z/frdm_kw41z.dts:62 */
		blue_pwm_led: pwm_led_0 {
			pwms = < &tpm2 0x0 0x1312d00 0x1 >; /* in zephyr/boards/nxp/frdm_kw41z/frdm_kw41z.dts:63 */
			label = "User PWM LD1";             /* in zephyr/boards/nxp/frdm_kw41z/frdm_kw41z.dts:64 */
		};

		/* node '/pwmleds/pwm_led_1' defined in zephyr/boards/nxp/frdm_kw41z/frdm_kw41z.dts:67 */
		green_pwm_led: pwm_led_1 {
			pwms = < &tpm2 0x1 0x1312d00 0x1 >; /* in zephyr/boards/nxp/frdm_kw41z/frdm_kw41z.dts:68 */
			label = "User PWM LD2";             /* in zephyr/boards/nxp/frdm_kw41z/frdm_kw41z.dts:69 */
		};

		/* node '/pwmleds/pwm_led_2' defined in zephyr/boards/nxp/frdm_kw41z/frdm_kw41z.dts:72 */
		red_pwm_led: pwm_led_2 {
			pwms = < &tpm0 0x2 0x1312d00 0x1 >; /* in zephyr/boards/nxp/frdm_kw41z/frdm_kw41z.dts:73 */
			label = "User PWM LD3";             /* in zephyr/boards/nxp/frdm_kw41z/frdm_kw41z.dts:74 */
		};
	};

	/* node '/gpio_keys' defined in zephyr/boards/nxp/frdm_kw41z/frdm_kw41z.dts:78 */
	gpio_keys {
		compatible = "gpio-keys"; /* in zephyr/boards/nxp/frdm_kw41z/frdm_kw41z.dts:79 */

		/* node '/gpio_keys/button_0' defined in zephyr/boards/nxp/frdm_kw41z/frdm_kw41z.dts:81 */
		user_button_3: button_0 {
			label = "User SW3";         /* in zephyr/boards/nxp/frdm_kw41z/frdm_kw41z.dts:82 */
			gpios = < &gpioc 0x4 0x1 >; /* in zephyr/boards/nxp/frdm_kw41z/frdm_kw41z.dts:83 */
			zephyr,code = < 0xb >;      /* in zephyr/boards/nxp/frdm_kw41z/frdm_kw41z.dts:84 */
		};

		/* node '/gpio_keys/button_1' defined in zephyr/boards/nxp/frdm_kw41z/frdm_kw41z.dts:87 */
		user_button_4: button_1 {
			label = "User SW4";         /* in zephyr/boards/nxp/frdm_kw41z/frdm_kw41z.dts:88 */
			gpios = < &gpioc 0x5 0x1 >; /* in zephyr/boards/nxp/frdm_kw41z/frdm_kw41z.dts:89 */
			zephyr,code = < 0x2 >;      /* in zephyr/boards/nxp/frdm_kw41z/frdm_kw41z.dts:90 */
		};
	};

	/* node '/connector' defined in zephyr/boards/nxp/frdm_kw41z/frdm_kw41z.dts:94 */
	arduino_header: connector {
		compatible = "arduino-header-r3";          /* in zephyr/boards/nxp/frdm_kw41z/frdm_kw41z.dts:95 */
		#gpio-cells = < 0x2 >;                     /* in zephyr/boards/nxp/frdm_kw41z/frdm_kw41z.dts:96 */
		gpio-map-mask = < 0xffffffff 0xffffffc0 >; /* in zephyr/boards/nxp/frdm_kw41z/frdm_kw41z.dts:97 */
		gpio-map-pass-thru = < 0x0 0x3f >;         /* in zephyr/boards/nxp/frdm_kw41z/frdm_kw41z.dts:98 */
		gpio-map = < 0x1 0x0 &gpiob 0x12 0x0 >,
		           < 0x2 0x0 &gpiob 0x2 0x0 >,
		           < 0x3 0x0 &gpiob 0x3 0x0 >,
		           < 0x4 0x0 &gpiob 0x1 0x0 >,
		           < 0x6 0x0 &gpioc 0x6 0x0 >,
		           < 0x7 0x0 &gpioc 0x7 0x0 >,
		           < 0x8 0x0 &gpioc 0x13 0x0 >,
		           < 0x9 0x0 &gpioc 0x10 0x0 >,
		           < 0xa 0x0 &gpioc 0x4 0x0 >,
		           < 0xb 0x0 &gpioc 0x11 0x0 >,
		           < 0xc 0x0 &gpioc 0x12 0x0 >,
		           < 0xd 0x0 &gpioa 0x1 0x0 >,
		           < 0xe 0x0 &gpioa 0x0 0x0 >,
		           < 0xf 0x0 &gpioc 0x1 0x0 >,
		           < 0x10 0x0 &gpioa 0x13 0x0 >,
		           < 0x11 0x0 &gpioa 0x10 0x0 >,
		           < 0x12 0x0 &gpioa 0x11 0x0 >,
		           < 0x13 0x0 &gpioa 0x12 0x0 >,
		           < 0x14 0x0 &gpioc 0x3 0x0 >,
		           < 0x15 0x0 &gpioc 0x2 0x0 >;    /* in zephyr/boards/nxp/frdm_kw41z/frdm_kw41z.dts:99 */
	};
};
